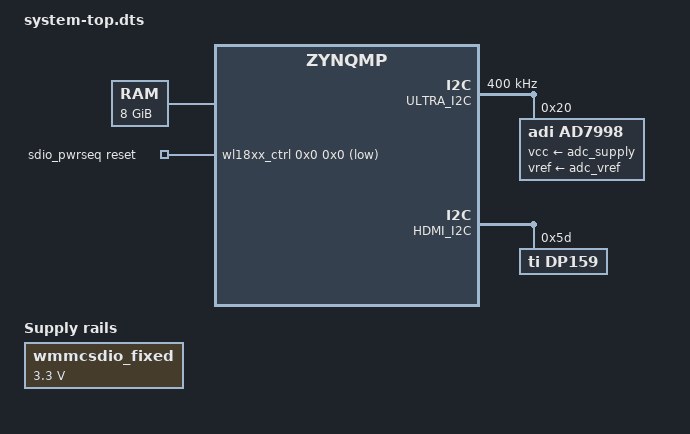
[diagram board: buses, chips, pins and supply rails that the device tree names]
/*
 * CAUTION: This file is automatically generated by Xilinx.
 * Version:  
 * Today is: Thu Oct 25 11:07:18 2018
 */


/dts-v1/;
/include/ "zynqmp.dtsi"
/include/ "zynqmp-clk-ccf.dtsi"
/include/ "pl.dtsi"
/include/ "pcw.dtsi"
/ {
	chosen {
		bootargs = "earlycon clk_ignore_unused";
		stdout-path = "serial0:115200n8";
	};
	
	aliases {
		ethernet0 = &gem2;
		i2c0 = &i2c0;
		serial0 = &uart1;
		spi0 = &qspi;
	};
	
	memory {
		device_type = "memory";
		reg = <0x0 0x0 0x0 0x7ff00000>, <0x00000008 0x00000000 0x00000001 0x80000000>;
	};
	
	wmmcsdio_fixed: fixedregulator {
		compatible = "regulator-fixed";
		regulator-name = "wmmcsdio_fixed";
		regulator-min-microvolt = <3300000>;
		regulator-max-microvolt = <3300000>;
		regulator-always-on;
		startup-delay-us = <70000>;
		enable-active-high;
	};
	
	sdio_pwrseq: sdio_pwrseq {
		compatible = "mmc-pwrseq-simple";
		reset-gpios = <&wl18xx_ctrl 0x0 0x0 0x1>;
		post-power-on-delay-ms = <1000>;
	};
};

&ULTRA_I2C {
	clock-frequency = <400000>;
	status = "okay";
	
	ad7998@20 {
		compatible = "adi,ad7998";
		reg = <0x20>;
		vcc-supply = <&adc_supply>;
		vref-supply = <&adc_vref>;
	};
};

&HDMI_I2C {
	status = "okay";

	dp159: hdmi-retimer@5d {
		status = "okay";
		compatible = "ti,dp159";
		reg = <0x5d>;
		#address-cells = <1>;
		#size-cells = <0>;
		#clock-cells = <0>;
	};
};
